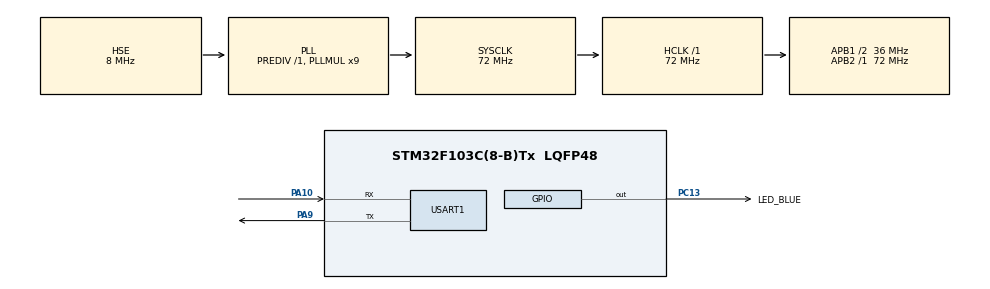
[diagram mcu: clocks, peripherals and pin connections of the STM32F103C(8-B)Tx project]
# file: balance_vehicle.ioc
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Mcu.Family=STM32F1
Mcu.Name=STM32F103C(8-B)Tx
Mcu.Package=LQFP48
NVIC.PriorityGroup=NVIC_PRIORITYGROUP_4
PA10.Mode=Asynchronous
PA10.Signal=USART1_RX
PA13.Mode=Serial_Wire
PA13.Signal=SYS_JTMS-SWDIO
PA14.Mode=Serial_Wire
PA14.Signal=SYS_JTCK-SWCLK
PA9.Mode=Asynchronous
PA9.Signal=USART1_TX
PC13-TAMPER-RTC.GPIO_Label=LED_BLUE
PC13-TAMPER-RTC.GPIO_PuPd=GPIO_PULLUP
PC13-TAMPER-RTC.GPIO_Speed=GPIO_SPEED_FREQ_LOW
PC13-TAMPER-RTC.PinState=GPIO_PIN_SET
PC13-TAMPER-RTC.Signal=GPIO_Output
PC14-OSC32_IN.Mode=LSE-External-Oscillator
PC14-OSC32_IN.Signal=RCC_OSC32_IN
PC15-OSC32_OUT.Mode=LSE-External-Oscillator
PC15-OSC32_OUT.Signal=RCC_OSC32_OUT
PD0-OSC_IN.Mode=HSE-External-Oscillator
PD0-OSC_IN.Signal=RCC_OSC_IN
PD1-OSC_OUT.Mode=HSE-External-Oscillator
PD1-OSC_OUT.Signal=RCC_OSC_OUT
ProjectManager.HeapSize=0x200
ProjectManager.StackSize=0x400
ProjectManager.TargetToolchain=MDK-ARM V5
RCC.AHBFreq_Value=72000000
RCC.APB1CLKDivider=RCC_HCLK_DIV2
RCC.APB1Freq_Value=36000000
RCC.APB1TimFreq_Value=72000000
RCC.APB2Freq_Value=72000000
RCC.APB2TimFreq_Value=72000000
RCC.HCLKFreq_Value=72000000
RCC.PLLMUL=RCC_PLL_MUL9
RCC.PLLSourceVirtual=RCC_PLLSOURCE_HSE
RCC.SYSCLKFreq_VALUE=72000000
RCC.SYSCLKSource=RCC_SYSCLKSOURCE_PLLCLK
RCC.USBFreq_Value=72000000
USART1.VirtualMode=VM_ASYNC
board=custom

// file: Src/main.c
/* USER CODE BEGIN Header */
/**
  ******************************************************************************
  * @file           : main.c
  * @brief          : Main program body
  ******************************************************************************
  * @attention
  *
  * <h2><center>&copy; Copyright (c) 2024 STMicroelectronics.
  * All rights reserved.</center></h2>
  *
  * This software component is licensed by ST under BSD 3-Clause license,
  * the "License"; You may not use this file except in compliance with the
  * License. You may obtain a copy of the License at:
  *                        opensource.org/licenses/BSD-3-Clause
  *
  ******************************************************************************
  */
/* USER CODE END Header */

#include "main.h"
#include "usart.h"
#include "gpio.h"

/* USER CODE BEGIN Includes */
#include "sys.h"
#include "delay.h"
#include "oled.h"
#include "bmp.h"
/* USER CODE END Includes */

void SystemClock_Config(void);
/* USER CODE BEGIN PFP */
void OLED_Show(void);
/* USER CODE END PFP */

int main(void)
{

  /* MCU Configuration--------------------------------------------------------*/

  /* Reset of all peripherals, Initializes the Flash interface and the Systick. */
  HAL_Init();

  /* Configure the system clock */
  SystemClock_Config();

  /* Initialize all configured peripherals */
  MX_GPIO_Init();
  MX_USART1_UART_Init();
  /* USER CODE BEGIN 2 */

  //OLED

  delay_init();
  OLED_Init();
  OLED_ColorTurn(0);//0正常显示，1 反色显示
  OLED_DisplayTurn(0);//0正常显示 1 屏幕翻转显示

  OLED_Refresh();

  /* USER CODE END 2 */

  /* Infinite loop */
  /* USER CODE BEGIN WHILE */
  while (1)
  {
	  //LED
	  HAL_GPIO_WritePin(LED_BLUE_GPIO_Port, LED_BLUE_Pin, GPIO_PIN_RESET);
	  HAL_Delay(500);  //sleep 500ms
	  HAL_GPIO_WritePin(LED_BLUE_GPIO_Port, LED_BLUE_Pin, GPIO_PIN_SET);
	  HAL_Delay(500);  //sleep 500ms

	  //USART1
	  printf("Hello c8t6!\n");

	  //OLED
	  OLED_Show();

    /* USER CODE END WHILE */

  }
}

void SystemClock_Config(void)
{
  RCC_OscInitTypeDef RCC_OscInitStruct = {0};
  RCC_ClkInitTypeDef RCC_ClkInitStruct = {0};

  /** Initializes the CPU, AHB and APB busses clocks
  */
  RCC_OscInitStruct.OscillatorType = RCC_OSCILLATORTYPE_HSE;
  RCC_OscInitStruct.HSEState = RCC_HSE_ON;
  RCC_OscInitStruct.HSEPredivValue = RCC_HSE_PREDIV_DIV1;
  RCC_OscInitStruct.HSIState = RCC_HSI_ON;
  RCC_OscInitStruct.PLL.PLLState = RCC_PLL_ON;
  RCC_OscInitStruct.PLL.PLLSource = RCC_PLLSOURCE_HSE;
  RCC_OscInitStruct.PLL.PLLMUL = RCC_PLL_MUL9;
  if (HAL_RCC_OscConfig(&RCC_OscInitStruct) != HAL_OK)
  {
    Error_Handler();
  }
  /** Initializes the CPU, AHB and APB busses clocks
  */
  RCC_ClkInitStruct.ClockType = RCC_CLOCKTYPE_HCLK|RCC_CLOCKTYPE_SYSCLK
                              |RCC_CLOCKTYPE_PCLK1|RCC_CLOCKTYPE_PCLK2;
  RCC_ClkInitStruct.SYSCLKSource = RCC_SYSCLKSOURCE_PLLCLK;
  RCC_ClkInitStruct.AHBCLKDivider = RCC_SYSCLK_DIV1;
  RCC_ClkInitStruct.APB1CLKDivider = RCC_HCLK_DIV2;
  RCC_ClkInitStruct.APB2CLKDivider = RCC_HCLK_DIV1;

  if (HAL_RCC_ClockConfig(&RCC_ClkInitStruct, FLASH_LATENCY_2) != HAL_OK)
  {
    Error_Handler();
  }
}

/* USER CODE BEGIN 4 */
void OLED_Show(){
    u8 t;
    t=' ';
	OLED_ShowPicture(0,0,128,8,BMP1);
	delay_ms(500);
	OLED_Clear();
	OLED_ShowChinese(0,0,0,16);//中
	OLED_ShowChinese(18,0,1,16);//景
	OLED_ShowChinese(36,0,2,16);//园
	OLED_ShowChinese(54,0,3,16);//电
	OLED_ShowChinese(72,0,4,16);//子
	OLED_ShowChinese(90,0,5,16);//科
	OLED_ShowChinese(108,0,6,16);//技
	OLED_ShowString(8,16,"ZHONGJINGYUAN",16);
	OLED_ShowString(20,32,"2014/05/01",16);
	OLED_ShowString(0,48,"ASCII:",16);
	OLED_ShowString(63,48,"CODE:",16);
	OLED_ShowChar(48,48,t,16);//显示ASCII字符
	t++;
	if(t>'~')t=' ';
	OLED_ShowNum(103,48,t,3,16);
	OLED_Refresh();
	delay_ms(500);
	OLED_Clear();
	OLED_ShowChinese(0,0,0,16);  //16*16 中
	OLED_ShowChinese(16,0,0,24); //24*24 中
    OLED_ShowChinese(24,20,0,32);//32*32 中
	OLED_ShowChinese(64,0,0,64); //64*64 中
    OLED_Refresh();
	delay_ms(500);
  	OLED_Clear();
	OLED_ShowString(0,0,"ABC",12);//6*12 “ABC”
	OLED_ShowString(0,12,"ABC",16);//8*16 “ABC”
    OLED_ShowString(0,28,"ABC",24);//12*24 “ABC”
	OLED_Refresh();
    delay_ms(500);
    OLED_ScrollDisplay(11,4);
}
/* USER CODE END 4 */

void Error_Handler(void)
{
}

/************************ (C) COPYRIGHT STMicroelectronics *****END OF FILE****/
